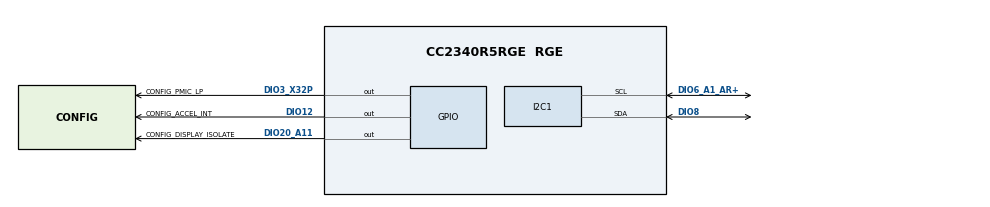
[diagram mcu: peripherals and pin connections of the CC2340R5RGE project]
/**
 *
 * @cliArgs --device "CC2340R5RGE" --part "Default" --package "RGE" --rtos "nortos" --product "simplelink_lowpower_f3_sdk@9.21.00.36"
 * @versions {"tool":"1.28.1+4785"}
 */

/**
 * Import the modules used in this configuration.
 */
const CCFG  = scripting.addModule("/ti/devices/CCFG");
const Board = scripting.addModule("/ti/drivers/Board");
const GPIO  = scripting.addModule("/ti/drivers/GPIO");
const GPIO1 = GPIO.addInstance();
const GPIO2 = GPIO.addInstance();
const GPIO3 = GPIO.addInstance();
const I2C   = scripting.addModule("/ti/drivers/I2C", {}, false);
const I2C1  = I2C.addInstance();

/**
 * Write custom configuration values to the imported modules.
 */
CCFG.srcClkLF           = "LF RCOSC";
CCFG.ccfgTemplate.$name = "ti_devices_CCFG_CCFGCC23X0Template0";

Board.generateInitializationFunctions = false;

GPIO1.$name              = "CONFIG_DISPLAY_ISOLATE";
GPIO1.mode               = "Output";
GPIO1.initialOutputState = "High";
GPIO1.gpioPin.$assign    = "DIO20_A11";

GPIO2.$name           = "CONFIG_PMIC_LP";
GPIO2.mode            = "Output";
GPIO2.gpioPin.$assign = "DIO3_X32P";

GPIO3.$name           = "CONFIG_ACCEL_INT";
GPIO3.gpioPin.$assign = "DIO12";

I2C1.$name              = "CONFIG_I2C_0";
I2C1.maxBitRate         = 100;
I2C1.i2c.sdaPin.$assign = "DIO8";
I2C1.i2c.sclPin.$assign = "DIO6_A1_AR+";

/**
 * Pinmux solution for unlocked pins/peripherals. This ensures that minor changes to the automatic solver in a future
 * version of the tool will not impact the pinmux you originally saw.  These lines can be completely deleted in order to
 * re-solve from scratch.
 */
I2C1.i2c.$suggestSolution = "I2C0";
